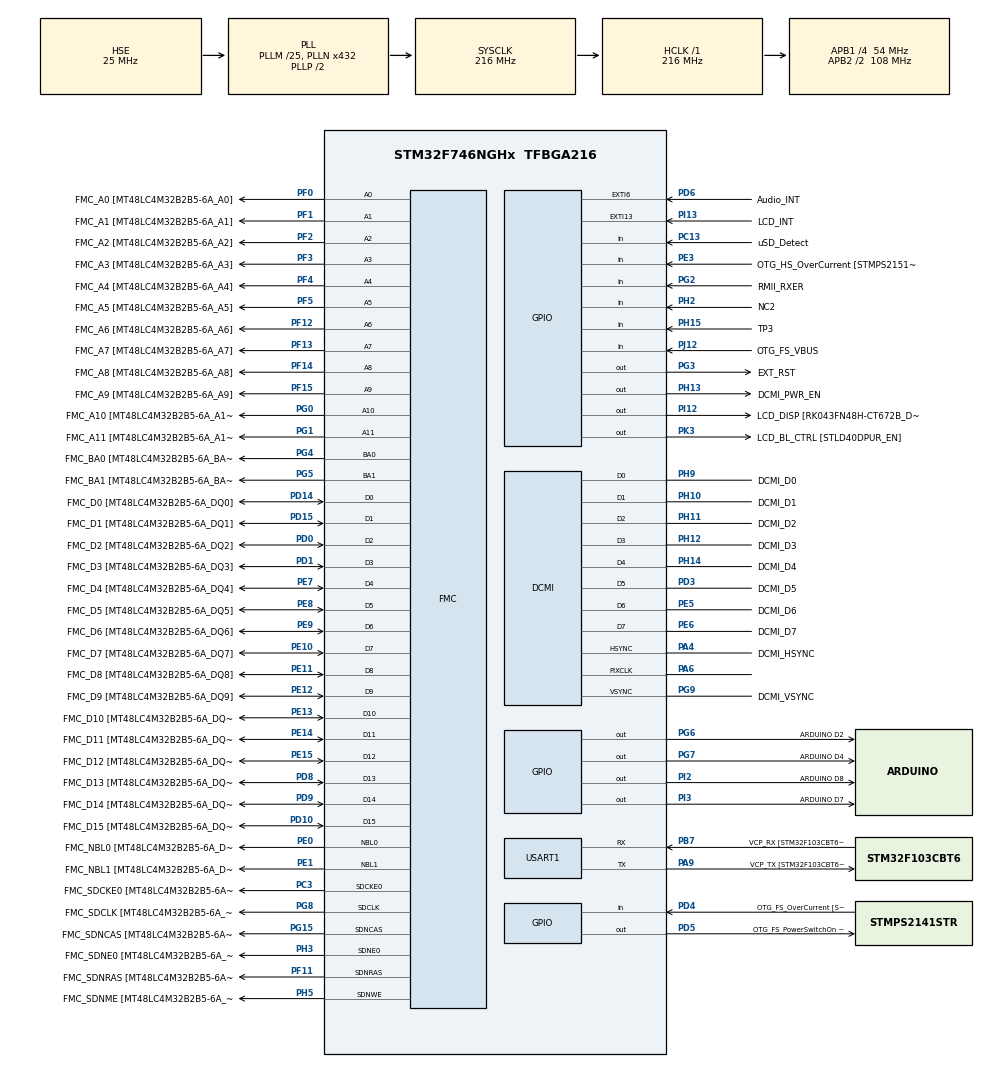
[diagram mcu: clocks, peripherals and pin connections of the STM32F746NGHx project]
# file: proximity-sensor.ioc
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CORTEX_M7.ART_ACCLERATOR_ENABLE=1
CORTEX_M7.CPU_DCache=Enabled
CORTEX_M7.CPU_ICache=Enabled
CORTEX_M7.PREFETCH_ENABLE=1
DCMI.PCKPolarity=DCMI_PCKPOLARITY_RISING
DCMI.VSPolarity=DCMI_VSPOLARITY_HIGH
Dma.DCMI.0.Direction=DMA_PERIPH_TO_MEMORY
Dma.DCMI.0.FIFOMode=DMA_FIFOMODE_ENABLE
Dma.DCMI.0.FIFOThreshold=DMA_FIFO_THRESHOLD_FULL
Dma.DCMI.0.Instance=DMA2_Stream1
Dma.DCMI.0.MemBurst=DMA_MBURST_INC4
Dma.DCMI.0.MemDataAlignment=DMA_MDATAALIGN_WORD
Dma.DCMI.0.MemInc=DMA_MINC_ENABLE
Dma.DCMI.0.Mode=DMA_CIRCULAR
Dma.DCMI.0.PeriphBurst=DMA_PBURST_SINGLE
Dma.DCMI.0.PeriphDataAlignment=DMA_PDATAALIGN_WORD
Dma.DCMI.0.PeriphInc=DMA_PINC_DISABLE
Dma.DCMI.0.Priority=DMA_PRIORITY_HIGH
Dma.Request0=DCMI
Mcu.Family=STM32F7
Mcu.Name=STM32F746NGHx
Mcu.Package=TFBGA216
NVIC.DCMI_IRQn=true\:0\:0\:false\:false\:true\:true
NVIC.DMA2_Stream1_IRQn=true\:0\:0\:false\:false\:true\:false
NVIC.PriorityGroup=NVIC_PRIORITYGROUP_4
NVIC.USART1_IRQn=true\:0\:0\:false\:false\:true\:true
PA0/WKUP.GPIO_Label=ARDUINO A0
PA0/WKUP.GPIO_Mode=GPIO_MODE_ANALOG
PA0/WKUP.GPIO_PuPd=GPIO_NOPULL
PA0/WKUP.Signal=ADCx_IN0
PA1.GPIO_Label=RMII_REF_CLK [LAN8742A-CZ-TR_REFCLK0]
PA1.Signal=ETH_REF_CLK
PA10.GPIO_Label=OTG_FS_ID
PA10.Signal=USB_OTG_FS_ID
PA11.GPIO_Label=OTG_FS_N
PA11.Signal=USB_OTG_FS_DM
PA12.GPIO_Label=OTG_FS_P
PA12.Signal=USB_OTG_FS_DP
PA13.GPIO_Label=SWDIO
PA13.Mode=Serial_Wire
PA13.Signal=SYS_JTMS-SWDIO
PA14.GPIO_Label=SWCLK
PA14.Mode=Serial_Wire
PA14.Signal=SYS_JTCK-SWCLK
PA15.GPIO_Label=ARDUINO PWM/D9
PA15.GPIO_ModeDefaultPP=GPIO_MODE_AF_PP
PA15.GPIO_PuPd=GPIO_NOPULL
PA15.GPIO_Speed=GPIO_SPEED_FREQ_LOW
PA15.Signal=S_TIM2_CH1_ETR
PA2.GPIO_Label=RMII_MDIO [LAN8742A-CZ-TR_MDIO]
PA2.Signal=ETH_MDIO
PA3.GPIO_Label=ULPI_D0 [USB3320C-EZK_D0]
PA3.Signal=USB_OTG_HS_ULPI_D0
PA4.GPIO_Label=DCMI_HSYNC
PA4.Mode=Slave_8_bits_External_Synchro
PA4.Signal=DCMI_HSYNC
PA5.GPIO_Label=ULPI_CLK [USB3320C-EZK_CLKOUT]
PA5.Signal=USB_OTG_HS_ULPI_CK
PA6.Mode=Slave_8_bits_External_Synchro
PA6.Signal=DCMI_PIXCLK
PA7.GPIO_Label=RMII_CRS_DV [LAN8742A-CZ-TR_CRS_DV]
PA7.Signal=ETH_CRS_DV
PA8.GPIO_Label=ARDUINO PWM/D5
PA8.GPIO_ModeDefaultPP=GPIO_MODE_AF_PP
PA8.GPIO_PuPd=GPIO_NOPULL
PA8.GPIO_Speed=GPIO_SPEED_FREQ_LOW
PA8.Signal=S_TIM1_CH1
PA9.GPIO_Label=VCP_TX [STM32F103CBT6_PA3]
PA9.GPIO_Mode=GPIO_MODE_AF_PP
PA9.GPIO_PuPd=GPIO_NOPULL
PA9.GPIO_Speed=GPIO_SPEED_FREQ_LOW
PA9.Mode=Asynchronous
PA9.Signal=USART1_TX
PB0.GPIO_Label=ULPI_D1 [USB3320C-EZK_D1]
PB0.Signal=USB_OTG_HS_ULPI_D1
PB1.GPIO_Label=ULPI_D2 [USB3320C-EZK_D2]
PB1.Signal=USB_OTG_HS_ULPI_D2
PB10.GPIO_Label=ULPI_D3 [USB3320C-EZK_D3]
PB10.Signal=USB_OTG_HS_ULPI_D3
PB11.GPIO_Label=ULPI_D4 [USB3320C-EZK_D4]
PB11.Signal=USB_OTG_HS_ULPI_D4
PB12.GPIO_Label=ULPI_D5 [USB3320C-EZK_D5]
PB12.Signal=USB_OTG_HS_ULPI_D5
PB13.GPIO_Label=ULPI_D6 [USB3320C-EZK_D6]
PB13.Signal=USB_OTG_HS_ULPI_D6
PB14.GPIO_Label=ARDUINO MISO/D12
PB14.GPIO_Mode=GPIO_MODE_AF_PP
PB14.GPIO_PuPd=GPIO_NOPULL
PB14.GPIO_Speed=GPIO_SPEED_FREQ_LOW
PB14.Signal=SPI2_MISO
PB15.GPIO_Label=ARDUINO MOSI/PWM/D11
PB15.GPIO_Mode=GPIO_MODE_AF_PP
PB15.GPIO_PuPd=GPIO_NOPULL
PB15.GPIO_Speed=GPIO_SPEED_FREQ_LOW
PB15.Signal=SPI2_MOSI
PB2.Signal=QUADSPI_CLK
PB3.GPIO_Label=SWO
PB3.Signal=SYS_JTDO-SWO
PB4.GPIO_Label=ARDUINO PWM/D3
PB4.GPIO_ModeDefaultPP=GPIO_MODE_AF_PP
PB4.GPIO_PuPd=GPIO_NOPULL
PB4.GPIO_Speed=GPIO_SPEED_FREQ_LOW
PB4.Signal=S_TIM3_CH1
PB5.GPIO_Label=ULPI_D7 [USB3320C-EZK_D7]
PB5.Signal=USB_OTG_HS_ULPI_D7
PB6.GPIO_Label=QSPI_NCS [N25Q128A13EF840E_S]
PB6.Signal=QUADSPI_BK1_NCS
PB7.GPIO_Label=VCP_RX [STM32F103CBT6_PA2]
PB7.GPIO_Mode=GPIO_MODE_AF_PP
PB7.GPIO_PuPd=GPIO_NOPULL
PB7.GPIO_Speed=GPIO_SPEED_FREQ_LOW
PB7.Mode=Asynchronous
PB7.Signal=USART1_RX
PB8.GPIO_Label=DCMI_SCL
PB8.GPIO_Mode=GPIO_MODE_AF_OD
PB8.GPIO_PuPd=GPIO_NOPULL
PB8.GPIO_Speed=GPIO_SPEED_FREQ_LOW
PB8.Signal=I2C1_SCL
PB9.GPIO_Label=DCMI_SDA
PB9.GPIO_Mode=GPIO_MODE_AF_OD
PB9.GPIO_PuPd=GPIO_NOPULL
PB9.GPIO_Speed=GPIO_SPEED_FREQ_LOW
PB9.Signal=I2C1_SDA
PC0.GPIO_Label=ULPI_STP [USB3320C-EZK_STP]
PC0.Signal=USB_OTG_HS_ULPI_STP
PC1.GPIO_Label=RMII_MDC [LAN8742A-CZ-TR_MDC]
PC1.Signal=ETH_MDC
PC10.GPIO_Label=SDMMC_D2
PC10.Signal=SDMMC1_D2
PC11.GPIO_Label=SDMMC_D3
PC11.Signal=SDMMC1_D3
PC12.GPIO_Label=SDMMC_CK
PC12.Signal=SDMMC1_CK
PC13.GPIO_Label=uSD_Detect
PC13.Signal=GPIO_Input
PC14/OSC32_IN.GPIO_Label=RCC_OSC32_IN
PC14/OSC32_IN.Mode=LSE-External-Oscillator
PC14/OSC32_IN.Signal=RCC_OSC32_IN
PC15/OSC32_OUT.GPIO_Label=RCC_OSC32_OUT
PC15/OSC32_OUT.Mode=LSE-External-Oscillator
PC15/OSC32_OUT.Signal=RCC_OSC32_OUT
PC2.GPIO_Label=ULPI_DIR [USB3320C-EZK_DIR]
PC2.Signal=USB_OTG_HS_ULPI_DIR
PC3.GPIO_Label=FMC_SDCKE0 [MT48LC4M32B2B5-6A_CKE]
PC3.Mode=SdramChipSelect1_1
PC3.Signal=FMC_SDCKE0
PC4.GPIO_Label=RMII_RXD0 [LAN8742A-CZ-TR_RXD0]
PC4.Signal=ETH_RXD0
PC5.GPIO_Label=RMII_RXD1 [LAN8742A-CZ-TR_RXD1]
PC5.Signal=ETH_RXD1
PC6.GPIO_Label=ARDUINO TX/D1
PC6.Signal=USART6_TX
PC7.GPIO_Label=ARDUINO RX/D0
PC7.Signal=USART6_RX
PC8.Signal=SDMMC1_D0
PC9.Signal=SDMMC1_D1
PD0.GPIO_Label=FMC_D2 [MT48LC4M32B2B5-6A_DQ2]
PD0.Signal=FMC_D2_DA2
PD1.GPIO_Label=FMC_D3 [MT48LC4M32B2B5-6A_DQ3]
PD1.Signal=FMC_D3_DA3
PD10.GPIO_Label=FMC_D15 [MT48LC4M32B2B5-6A_DQ15]
PD10.Signal=FMC_D15_DA15
PD11.GPIO_Label=QSPI_D0 [N25Q128A13EF840E_DQ0]
PD11.Signal=QUADSPI_BK1_IO0
PD12.GPIO_Label=QSPI_D1 [N25Q128A13EF840E_DQ1]
PD12.Signal=QUADSPI_BK1_IO1
PD13.GPIO_Label=QSPI_D3 [N25Q128A13EF840E_DQ3]
PD13.Signal=QUADSPI_BK1_IO3
PD14.GPIO_Label=FMC_D0 [MT48LC4M32B2B5-6A_DQ0]
PD14.Signal=FMC_D0_DA0
PD15.GPIO_Label=FMC_D1 [MT48LC4M32B2B5-6A_DQ1]
PD15.Signal=FMC_D1_DA1
PD2.GPIO_Label=SDMMC_CMD
PD2.Signal=SDMMC1_CMD
PD3.GPIO_Label=DCMI_D5
PD3.Mode=Slave_8_bits_External_Synchro
PD3.Signal=DCMI_D5
PD4.GPIO_Label=OTG_FS_OverCurrent [STMPS2141STR_Fault]
PD4.Signal=GPIO_Input
PD5.GPIO_Label=OTG_FS_PowerSwitchOn [STMPS2141STR_EN]
PD5.PinState=GPIO_PIN_SET
PD5.Signal=GPIO_Output
PD6.GPIO_Label=Audio_INT
PD6.GPIO_ModeDefaultEXTI=GPIO_MODE_EVT_RISING
PD6.Signal=GPXTI6
PD7.GPIO_Label=SPDIF_RX0 [74LVC1G04SE_4]
PD7.Signal=SPDIFRX_IN0
PD8.GPIO_Label=FMC_D13 [MT48LC4M32B2B5-6A_DQ13]
PD8.Signal=FMC_D13_DA13
PD9.GPIO_Label=FMC_D14 [MT48LC4M32B2B5-6A_DQ14]
PD9.Signal=FMC_D14_DA14
PE0.GPIO_Label=FMC_NBL0 [MT48LC4M32B2B5-6A_DQM0]
PE0.Signal=FMC_NBL0
PE1.GPIO_Label=FMC_NBL1 [MT48LC4M32B2B5-6A_DQM1]
PE1.Signal=FMC_NBL1
PE10.GPIO_Label=FMC_D7 [MT48LC4M32B2B5-6A_DQ7]
PE10.Signal=FMC_D7_DA7
PE11.GPIO_Label=FMC_D8 [MT48LC4M32B2B5-6A_DQ8]
PE11.Signal=FMC_D8_DA8
PE12.GPIO_Label=FMC_D9 [MT48LC4M32B2B5-6A_DQ9]
PE12.Signal=FMC_D9_DA9
PE13.GPIO_Label=FMC_D10 [MT48LC4M32B2B5-6A_DQ10]
PE13.Signal=FMC_D10_DA10
PE14.GPIO_Label=FMC_D11 [MT48LC4M32B2B5-6A_DQ11]
PE14.Signal=FMC_D11_DA11
PE15.GPIO_Label=FMC_D12 [MT48LC4M32B2B5-6A_DQ12]
PE15.Signal=FMC_D12_DA12
PE2.GPIO_Label=QSPI_D2 [N25Q128A13EF840E_DQ2]
PE2.Signal=QUADSPI_BK1_IO2
PE3.GPIO_Label=OTG_HS_OverCurrent [STMPS2151STR_FAULT]
PE3.Signal=GPIO_Input
PE4.GPIO_Label=LCD_B0 [RK043FN48H-CT672B_B0]
PE4.Signal=LTDC_B0
PE5.GPIO_Label=DCMI_D6
PE5.Mode=Slave_8_bits_External_Synchro
PE5.Signal=DCMI_D6
PE6.GPIO_Label=DCMI_D7
PE6.Mode=Slave_8_bits_External_Synchro
PE6.Signal=DCMI_D7
PE7.GPIO_Label=FMC_D4 [MT48LC4M32B2B5-6A_DQ4]
PE7.Signal=FMC_D4_DA4
PE8.GPIO_Label=FMC_D5 [MT48LC4M32B2B5-6A_DQ5]
PE8.Signal=FMC_D5_DA5
PE9.GPIO_Label=FMC_D6 [MT48LC4M32B2B5-6A_DQ6]
PE9.Signal=FMC_D6_DA6
PF0.GPIO_Label=FMC_A0 [MT48LC4M32B2B5-6A_A0]
PF0.Signal=FMC_A0
PF1.GPIO_Label=FMC_A1 [MT48LC4M32B2B5-6A_A1]
PF1.Signal=FMC_A1
PF10.GPIO_Label=ARDUINO A1
PF10.GPIO_Mode=GPIO_MODE_ANALOG
PF10.GPIO_PuPd=GPIO_NOPULL
PF10.Signal=ADC3_IN8
PF11.GPIO_Label=FMC_SDNRAS [MT48LC4M32B2B5-6A_RAS]
PF11.Signal=FMC_SDNRAS
PF12.GPIO_Label=FMC_A6 [MT48LC4M32B2B5-6A_A6]
PF12.Signal=FMC_A6
PF13.GPIO_Label=FMC_A7 [MT48LC4M32B2B5-6A_A7]
PF13.Signal=FMC_A7
PF14.GPIO_Label=FMC_A8 [MT48LC4M32B2B5-6A_A8]
PF14.Signal=FMC_A8
PF15.GPIO_Label=FMC_A9 [MT48LC4M32B2B5-6A_A9]
PF15.Signal=FMC_A9
PF2.GPIO_Label=FMC_A2 [MT48LC4M32B2B5-6A_A2]
PF2.Signal=FMC_A2
PF3.GPIO_Label=FMC_A3 [MT48LC4M32B2B5-6A_A3]
PF3.Signal=FMC_A3
PF4.GPIO_Label=FMC_A4 [MT48LC4M32B2B5-6A_A4]
PF4.Signal=FMC_A4
PF5.GPIO_Label=FMC_A5 [MT48LC4M32B2B5-6A_A5]
PF5.Signal=FMC_A5
PF6.GPIO_Label=ARDUINO A5
PF6.GPIO_Mode=GPIO_MODE_ANALOG
PF6.GPIO_PuPd=GPIO_NOPULL
PF6.Signal=ADC3_IN4
PF7.GPIO_Label=ARDUINO A4
PF7.GPIO_Mode=GPIO_MODE_ANALOG
PF7.GPIO_PuPd=GPIO_NOPULL
PF7.Signal=ADC3_IN5
PF8.GPIO_Label=ARDUINO A3
PF8.GPIO_Mode=GPIO_MODE_ANALOG
PF8.GPIO_PuPd=GPIO_NOPULL
PF8.Signal=ADC3_IN6
PF9.GPIO_Label=ARDUINO A2
PF9.GPIO_Mode=GPIO_MODE_ANALOG
PF9.GPIO_PuPd=GPIO_NOPULL
PF9.Signal=ADC3_IN7
PG0.GPIO_Label=FMC_A10 [MT48LC4M32B2B5-6A_A10]
PG0.Signal=FMC_A10
PG1.GPIO_Label=FMC_A11 [MT48LC4M32B2B5-6A_A11]
PG1.Signal=FMC_A11
PG10.GPIO_Label=SAI2_SDB [WM8994ECS/R_ADCDAT1]
PG10.Signal=SAI2_SD_B
PG11.GPIO_Label=RMII_TX_EN [LAN8742A-CZ-TR_TXEN]
PG11.Signal=ETH_TX_EN
PG12.GPIO_Label=LCD_B4 [RK043FN48H-CT672B_B4]
PG12.Signal=LTDC_B4
PG13.GPIO_Label=RMII_TXD0 [LAN8742A-CZ-TR_TXD0]
PG13.Signal=ETH_TXD0
PG14.GPIO_Label=RMII_TXD1 [LAN8742A-CZ-TR_TXD1]
PG14.Signal=ETH_TXD1
PG15.GPIO_Label=FMC_SDNCAS [MT48LC4M32B2B5-6A_CAS]
PG15.Signal=FMC_SDNCAS
PG2.GPIO_Label=RMII_RXER
PG2.Signal=GPIO_Input
PG3.GPIO_Label=EXT_RST
PG3.Signal=GPIO_Output
PG4.GPIO_Label=FMC_BA0 [MT48LC4M32B2B5-6A_BA0]
PG4.Signal=FMC_A14_BA0
PG5.GPIO_Label=FMC_BA1 [MT48LC4M32B2B5-6A_BA1]
PG5.Signal=FMC_A15_BA1
PG6.GPIO_Label=ARDUINO D2
PG6.Signal=GPIO_Output
PG7.GPIO_Label=ARDUINO D4
PG7.Signal=GPIO_Output
PG8.GPIO_Label=FMC_SDCLK [MT48LC4M32B2B5-6A_CLK]
PG8.Signal=FMC_SDCLK
PG9.GPIO_Label=DCMI_VSYNC
PG9.Mode=Slave_8_bits_External_Synchro
PG9.Signal=DCMI_VSYNC
PH0/OSC_IN.GPIO_Label=OSC_25M [NZ2520SB-25.00M_OUT]
PH0/OSC_IN.Mode=HSE-External-Oscillator
PH0/OSC_IN.Signal=RCC_OSC_IN
PH1/OSC_OUT.Mode=HSE-External-Oscillator
PH1/OSC_OUT.Signal=RCC_OSC_OUT
PH10.GPIO_Label=DCMI_D1
PH10.Mode=Slave_8_bits_External_Synchro
PH10.Signal=DCMI_D1
PH11.GPIO_Label=DCMI_D2
PH11.Mode=Slave_8_bits_External_Synchro
PH11.Signal=DCMI_D2
PH12.GPIO_Label=DCMI_D3
PH12.Mode=Slave_8_bits_External_Synchro
PH12.Signal=DCMI_D3
PH13.GPIO_Label=DCMI_PWR_EN
PH13.GPIO_Speed=GPIO_SPEED_FREQ_HIGH
PH13.Signal=GPIO_Output
PH14.GPIO_Label=DCMI_D4
PH14.Mode=Slave_8_bits_External_Synchro
PH14.Signal=DCMI_D4
PH15.GPIO_Label=TP3
PH15.Signal=GPIO_Input
PH2.GPIO_Label=NC2
PH2.Signal=GPIO_Input
PH3.GPIO_Label=FMC_SDNE0 [MT48LC4M32B2B5-6A_CS]
PH3.Mode=SdramChipSelect1_1
PH3.Signal=FMC_SDNE0
PH4.GPIO_Label=ULPI_NXT [USB3320C-EZK_NXT]
PH4.Signal=USB_OTG_HS_ULPI_NXT
PH5.GPIO_Label=FMC_SDNME [MT48LC4M32B2B5-6A_WE]
PH5.Signal=FMC_SDNWE
PH6.GPIO_Label=ARDUINO PWM/D6
PH6.Signal=S_TIM12_CH1
PH7.GPIO_Label=LCD_SCL [RK043FN48H-CT672B_SCL]
PH7.Signal=I2C3_SCL
PH8.GPIO_Label=LCD_SDA [RK043FN48H-CT672B_SDA]
PH8.Signal=I2C3_SDA
PH9.GPIO_Label=DCMI_D0
PH9.Mode=Slave_8_bits_External_Synchro
PH9.Signal=DCMI_D0
PI0.GPIO_Label=ARDUINO PWM/CS/D10
PI0.GPIO_ModeDefaultPP=GPIO_MODE_AF_PP
PI0.GPIO_PuPd=GPIO_NOPULL
PI0.GPIO_Speed=GPIO_SPEED_FREQ_LOW
PI0.Signal=S_TIM5_CH4
PI1.GPIO_Label=ARDUINO SCK/D13
PI1.GPIO_Mode=GPIO_MODE_AF_PP
PI1.GPIO_PuPd=GPIO_NOPULL
PI1.GPIO_Speed=GPIO_SPEED_FREQ_LOW
PI1.Signal=SPI2_SCK
PI10.GPIO_Label=LCD_HSYNC [RK043FN48H-CT672B_HSYNC]
PI10.Signal=LTDC_HSYNC
PI12.GPIO_Label=LCD_DISP [RK043FN48H-CT672B_DISP] 
PI12.Signal=GPIO_Output
PI13.GPIO_Label=LCD_INT
PI13.GPIO_ModeDefaultEXTI=GPIO_MODE_EVT_RISING
PI13.Signal=GPXTI13
PI14.GPIO_Label=LCD_CLK [RK043FN48H-CT672B_CLK]
PI14.Signal=LTDC_CLK
PI15.GPIO_Label=LCD_R0 [RK043FN48H-CT672B_R0]
PI15.Signal=LTDC_R0
PI2.GPIO_Label=ARDUINO D8
PI2.Signal=GPIO_Output
PI3.GPIO_Label=ARDUINO D7
PI3.Signal=GPIO_Output
PI4.GPIO_Label=SAI2_MCLKA [WM8994ECS/R_MCLK1]
PI4.Signal=SAI2_MCLK_A
PI5.GPIO_Label=SAI2_SCKA [WM8994ECS/R_BCLK1]
PI5.Signal=SAI2_SCK_A
PI6.GPIO_Label=SAI2_SDA [WM8994ECS/R_DACDAT1]
PI6.Signal=SAI2_SD_A
PI7.GPIO_Label=SAI2_FSA [WM8994ECS/R_LRCLK1]
PI7.Signal=SAI2_FS_A
PI8.GPIO_Label=NC1 [TP2]
PI8.Signal=RTC_TS
PI9.GPIO_Label=LCD_VSYNC [RK043FN48H-CT672B_VSYNC]
PI9.Signal=LTDC_VSYNC
PJ0.GPIO_Label=LCD_R1 [RK043FN48H-CT672B_R1]
PJ0.Signal=LTDC_R1
PJ1.GPIO_Label=LCD_R2 [RK043FN48H-CT672B_R2]
PJ1.Signal=LTDC_R2
PJ10.GPIO_Label=LCD_G3 [RK043FN48H-CT672B_G3]
PJ10.Signal=LTDC_G3
PJ11.GPIO_Label=LCD_G4 [RK043FN48H-CT672B_G4]
PJ11.Signal=LTDC_G4
PJ12.GPIO_Label=OTG_FS_VBUS
PJ12.Signal=GPIO_Input
PJ13.GPIO_Label=LCD_B1 [RK043FN48H-CT672B_B1]
PJ13.Signal=LTDC_B1
PJ14.GPIO_Label=LCD_B2 [RK043FN48H-CT672B_B2]
PJ14.Signal=LTDC_B2
PJ15.GPIO_Label=LCD_B3 [RK043FN48H-CT672B_B3]
PJ15.Signal=LTDC_B3
PJ2.GPIO_Label=LCD_R3 [RK043FN48H-CT672B_R3]
PJ2.Signal=LTDC_R3
PJ3.GPIO_Label=LCD_R4 [RK043FN48H-CT672B_R4]
PJ3.Signal=LTDC_R4
PJ4.GPIO_Label=LCD_R5 [RK043FN48H-CT672B_R5]
PJ4.Signal=LTDC_R5
PJ5.GPIO_Label=LCD_R6 [RK043FN48H-CT672B_R6]
PJ5.Signal=LTDC_R6
PJ6.GPIO_Label=LCD_R7 [RK043FN48H-CT672B_R7]
PJ6.Signal=LTDC_R7
PJ7.GPIO_Label=LCD_G0 [RK043FN48H-CT672B_G0]
PJ7.Signal=LTDC_G0
PJ8.GPIO_Label=LCD_G1 [RK043FN48H-CT672B_G1]
PJ8.Signal=LTDC_G1
PJ9.GPIO_Label=LCD_G2 [RK043FN48H-CT672B_G2]
PJ9.Signal=LTDC_G2
PK0.GPIO_Label=LCD_G5 [RK043FN48H-CT672B_G5]
PK0.Signal=LTDC_G5
PK1.GPIO_Label=LCD_G6 [RK043FN48H-CT672B_G6]
PK1.Signal=LTDC_G6
PK2.GPIO_Label=LCD_G7 [RK043FN48H-CT672B_G7]
PK2.Signal=LTDC_G7
PK3.GPIO_Label=LCD_BL_CTRL [STLD40DPUR_EN]
PK3.Signal=GPIO_Output
PK4.GPIO_Label=LCD_B5 [RK043FN48H-CT672B_B5]
PK4.Signal=LTDC_B5
PK5.GPIO_Label=LCD_B6 [RK043FN48H-CT672B_B6]
PK5.Signal=LTDC_B6
PK6.GPIO_Label=LCD_B7 [RK043FN48H-CT672B_B7]
PK6.Signal=LTDC_B7
PK7.GPIO_Label=LCD_DE [RK043FN48H-CT672B_DE]
PK7.Signal=LTDC_DE
ProjectManager.HeapSize=0x200
ProjectManager.StackSize=0x400
ProjectManager.TargetToolchain=TrueSTUDIO
RCC.AHBFreq_Value=216000000
RCC.APB1CLKDivider=RCC_HCLK_DIV4
RCC.APB1Freq_Value=54000000
RCC.APB1TimFreq_Value=108000000
RCC.APB2CLKDivider=RCC_HCLK_DIV2
RCC.APB2Freq_Value=108000000
RCC.APB2TimFreq_Value=216000000
RCC.CortexFreq_Value=216000000
RCC.HCLKFreq_Value=216000000
RCC.HSE_VALUE=25000000
RCC.HSI_VALUE=16000000
RCC.PLLI2SN=100
RCC.PLLM=25
RCC.PLLN=432
RCC.PLLQ=9
RCC.PLLSAIN=100
RCC.PLLSourceVirtual=RCC_PLLSOURCE_HSE
RCC.SDMMCClockSelection=RCC_SDMMC1CLKSOURCE_CLK48
RCC.SYSCLKFreq_VALUE=216000000
RCC.SYSCLKSource=RCC_SYSCLKSOURCE_PLLCLK
RCC.USBFreq_Value=48000000
RCC.VCOOutputFreq_Value=432000000
SH.ADCx_IN0.0=ADC3_IN0
SH.FMC_A0.0=FMC_A0,12b-sda1
SH.FMC_A1.0=FMC_A1,12b-sda1
SH.FMC_A10.0=FMC_A10,12b-sda1
SH.FMC_A11.0=FMC_A11,12b-sda1
SH.FMC_A14_BA0.0=FMC_BA0,FourSdramBanks1
SH.FMC_A15_BA1.0=FMC_BA1,FourSdramBanks1
SH.FMC_A2.0=FMC_A2,12b-sda1
SH.FMC_A3.0=FMC_A3,12b-sda1
SH.FMC_A4.0=FMC_A4,12b-sda1
SH.FMC_A5.0=FMC_A5,12b-sda1
SH.FMC_A6.0=FMC_A6,12b-sda1
SH.FMC_A7.0=FMC_A7,12b-sda1
SH.FMC_A8.0=FMC_A8,12b-sda1
SH.FMC_A9.0=FMC_A9,12b-sda1
SH.FMC_D0_DA0.0=FMC_D0,sd-16b-d1
SH.FMC_D10_DA10.0=FMC_D10,sd-16b-d1
SH.FMC_D11_DA11.0=FMC_D11,sd-16b-d1
SH.FMC_D12_DA12.0=FMC_D12,sd-16b-d1
SH.FMC_D13_DA13.0=FMC_D13,sd-16b-d1
SH.FMC_D14_DA14.0=FMC_D14,sd-16b-d1
SH.FMC_D15_DA15.0=FMC_D15,sd-16b-d1
SH.FMC_D1_DA1.0=FMC_D1,sd-16b-d1
SH.FMC_D2_DA2.0=FMC_D2,sd-16b-d1
SH.FMC_D3_DA3.0=FMC_D3,sd-16b-d1
SH.FMC_D4_DA4.0=FMC_D4,sd-16b-d1
SH.FMC_D5_DA5.0=FMC_D5,sd-16b-d1
SH.FMC_D6_DA6.0=FMC_D6,sd-16b-d1
SH.FMC_D7_DA7.0=FMC_D7,sd-16b-d1
SH.FMC_D8_DA8.0=FMC_D8,sd-16b-d1
SH.FMC_D9_DA9.0=FMC_D9,sd-16b-d1
SH.FMC_NBL0.0=FMC_NBL0,Sd2ByteEnable1
SH.FMC_NBL1.0=FMC_NBL1,Sd2ByteEnable1
SH.FMC_SDCLK.0=FMC_SDCLK,12b-sda1
SH.FMC_SDNCAS.0=FMC_SDNCAS,12b-sda1
SH.FMC_SDNRAS.0=FMC_SDNRAS,12b-sda1
SH.FMC_SDNWE.0=FMC_SDNWE,12b-sda1
SH.S_TIM12_CH1.0=TIM12_CH1
SH.S_TIM1_CH1.0=TIM1_CH1
SH.S_TIM2_CH1_ETR.0=TIM2_CH1
SH.S_TIM3_CH1.0=TIM3_CH1
SH.S_TIM5_CH4.0=TIM5_CH4
USART1.VirtualMode-Asynchronous=VM_ASYNC
USART1.WordLength=WORDLENGTH_8B
board=32F746GDISCOVERY

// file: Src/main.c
/**
  ******************************************************************************
  * @file           : main.c
  * @brief          : Main program body
  ******************************************************************************
  ** This notice applies to any and all portions of this file
  * that are not between comment pairs USER CODE BEGIN and
  * USER CODE END. Other portions of this file, whether
  * inserted by the user or by software development tools
  * are owned by their respective copyright owners.
  *
  * COPYRIGHT(c) 2018 STMicroelectronics
  *
  * Redistribution and use in source and binary forms, with or without modification,
  * are permitted provided that the following conditions are met:
  *   1. Redistributions of source code must retain the above copyright notice,
  *      this list of conditions and the following disclaimer.
  *   2. Redistributions in binary form must reproduce the above copyright notice,
  *      this list of conditions and the following disclaimer in the documentation
  *      and/or other materials provided with the distribution.
  *   3. Neither the name of STMicroelectronics nor the names of its contributors
  *      may be used to endorse or promote products derived from this software
  *      without specific prior written permission.
  *
  * THIS SOFTWARE IS PROVIDED BY THE COPYRIGHT HOLDERS AND CONTRIBUTORS "AS IS"
  * AND ANY EXPRESS OR IMPLIED WARRANTIES, INCLUDING, BUT NOT LIMITED TO, THE
  * IMPLIED WARRANTIES OF MERCHANTABILITY AND FITNESS FOR A PARTICULAR PURPOSE ARE
  * DISCLAIMED. IN NO EVENT SHALL THE COPYRIGHT HOLDER OR CONTRIBUTORS BE LIABLE
  * FOR ANY DIRECT, INDIRECT, INCIDENTAL, SPECIAL, EXEMPLARY, OR CONSEQUENTIAL
  * DAMAGES (INCLUDING, BUT NOT LIMITED TO, PROCUREMENT OF SUBSTITUTE GOODS OR
  * SERVICES; LOSS OF USE, DATA, OR PROFITS; OR BUSINESS INTERRUPTION) HOWEVER
  * CAUSED AND ON ANY THEORY OF LIABILITY, WHETHER IN CONTRACT, STRICT LIABILITY,
  * OR TORT (INCLUDING NEGLIGENCE OR OTHERWISE) ARISING IN ANY WAY OUT OF THE USE
  * OF THIS SOFTWARE, EVEN IF ADVISED OF THE POSSIBILITY OF SUCH DAMAGE.
  *
  ******************************************************************************
  */
#include "main.h"
#include "stm32f7xx_hal.h"
#include "dcmi.h"
#include "dma.h"
#include "usart.h"
#include "gpio.h"
#include "fmc.h"

/* USER CODE BEGIN Includes */
#include "usb_device.h"
#include "usbd_cdc_if.h"
#include "config.h"
#include "stm32746g_discovery.h"
#include "stm32746g_discovery_sdram.h"
#include "ov9655.h"
#include "rk043fn48h.h"
#include "fonts.h"
#include "camera.h"

#include "prox_sensor.h"
#include "prox_sensor_console.h"
/* USER CODE END Includes */

/* USER CODE BEGIN PV */
/* Private variables ---------------------------------------------------------*/

typedef struct
{
	uint32_t TextColor;
	uint32_t BackColor;
	sFONT
	*pFont;
}LCD_DrawPropTypeDef;

typedef struct
{
	int16_t X;
	int16_t Y;
}Point, *pPoint;

static LCD_DrawPropTypeDef DrawProp[2];

LTDC_HandleTypeDef hltdc;
LTDC_LayerCfgTypeDef layer_cfg;
static RCC_PeriphCLKInitTypeDef periph_clk_init_struct;

/* Image size */
uint32_t Im_size = 0;

/* USER CODE END PV */

void SystemClock_Config(void);

/* USER CODE BEGIN PFP */
/* Private function prototypes -----------------------------------------------*/

static void LTDC_Init(uint32_t , uint16_t , uint16_t , uint16_t, uint16_t);
void LCD_GPIO_Init(LTDC_HandleTypeDef *, void *);

/* USER CODE END PFP */

/* USER CODE BEGIN 0 */
static void MPU_Config (void)
{
  MPU_Region_InitTypeDef MPU_InitStruct;

  /* Disable the MPU */
  HAL_MPU_Disable();

  /* Configure the MPU attributes for SDRAM */
  MPU_InitStruct.Enable = MPU_REGION_ENABLE;
  MPU_InitStruct.BaseAddress = 0xC0000000;
  MPU_InitStruct.Size = MPU_REGION_SIZE_4MB;
  MPU_InitStruct.AccessPermission = MPU_REGION_FULL_ACCESS;
  MPU_InitStruct.IsBufferable = MPU_ACCESS_NOT_BUFFERABLE;
  MPU_InitStruct.IsCacheable = MPU_ACCESS_NOT_CACHEABLE;
  MPU_InitStruct.IsShareable = MPU_ACCESS_NOT_SHAREABLE;
  MPU_InitStruct.Number = MPU_REGION_NUMBER0;
  MPU_InitStruct.TypeExtField = MPU_TEX_LEVEL1;
  MPU_InitStruct.SubRegionDisable = 0x00;
  MPU_InitStruct.DisableExec = MPU_INSTRUCTION_ACCESS_DISABLE;

  HAL_MPU_ConfigRegion(&MPU_InitStruct);

  /* Enable the MPU */
  HAL_MPU_Enable(MPU_PRIVILEGED_DEFAULT);
}

void perform();

/* USER CODE END 0 */

int main(void)
{

  /* Enable I-Cache-------------------------------------------------------------*/
  SCB_EnableICache();

  /* Enable D-Cache-------------------------------------------------------------*/
  SCB_EnableDCache();

  /* MCU Configuration----------------------------------------------------------*/

  /* Reset of all peripherals, Initializes the Flash interface and the Systick. */
  HAL_Init();

  /* Configure the system clock */
  SystemClock_Config();

  /* Initialize all configured peripherals */
  MX_GPIO_Init();
  MX_DMA_Init();
  MX_DCMI_Init();
  MX_FMC_Init();
  MX_USART1_UART_Init();
  /* USER CODE BEGIN 2 */
  MX_USB_DEVICE_Init();
  ProxSensor_Init(FRAME_BUFFER);
  ProxSensor_Console_Init();

  LTDC_Init(FRAME_BUFFER, 0, 0, CAM_IMG_WIDTH, CAM_IMG_HEIGHT);
  BSP_SDRAM_Init();

#ifdef CAM_R_QQVGA
  CAMERA_Init(CAMERA_R160x120);
#elif defined CAM_R_QVGA
  CAMERA_Init(CAMERA_R320x240);
#elif defined CAM_R_VGA
  CAMERA_Init(CAMERA_R640x480);
#endif

  //Delay for the camera to output correct data
  HAL_Delay(1000);
  Im_size = CAM_IMG_SIZE * 2 / 4;
  MPU_Config();

  /* USER CODE END 2 */

  /* Infinite loop */
  /* USER CODE BEGIN WHILE */

  while (1)
  {
	  ProxSensor_Console_Perform();
	  perform();
  /* USER CODE END WHILE */

  }

}

void SystemClock_Config(void)
{

  RCC_OscInitTypeDef RCC_OscInitStruct;
  RCC_ClkInitTypeDef RCC_ClkInitStruct;
  RCC_PeriphCLKInitTypeDef PeriphClkInitStruct;

    /**Configure the main internal regulator output voltage
    */
  __HAL_RCC_PWR_CLK_ENABLE();

  __HAL_PWR_VOLTAGESCALING_CONFIG(PWR_REGULATOR_VOLTAGE_SCALE1);

    /**Initializes the CPU, AHB and APB busses clocks
    */
  RCC_OscInitStruct.OscillatorType = RCC_OSCILLATORTYPE_HSE;
  RCC_OscInitStruct.HSEState = RCC_HSE_ON;
  RCC_OscInitStruct.PLL.PLLState = RCC_PLL_ON;
  RCC_OscInitStruct.PLL.PLLSource = RCC_PLLSOURCE_HSE;
  RCC_OscInitStruct.PLL.PLLM = 25;
  RCC_OscInitStruct.PLL.PLLN = 432;
  RCC_OscInitStruct.PLL.PLLP = RCC_PLLP_DIV2;
  RCC_OscInitStruct.PLL.PLLQ = 9;
  if (HAL_RCC_OscConfig(&RCC_OscInitStruct) != HAL_OK)
  {
    _Error_Handler(__FILE__, __LINE__);
  }

    /**Activate the Over-Drive mode
    */
  if (HAL_PWREx_EnableOverDrive() != HAL_OK)
  {
    _Error_Handler(__FILE__, __LINE__);
  }

    /**Initializes the CPU, AHB and APB busses clocks
    */
  RCC_ClkInitStruct.ClockType = RCC_CLOCKTYPE_HCLK|RCC_CLOCKTYPE_SYSCLK
                              |RCC_CLOCKTYPE_PCLK1|RCC_CLOCKTYPE_PCLK2;
  RCC_ClkInitStruct.SYSCLKSource = RCC_SYSCLKSOURCE_PLLCLK;
  RCC_ClkInitStruct.AHBCLKDivider = RCC_SYSCLK_DIV1;
  RCC_ClkInitStruct.APB1CLKDivider = RCC_HCLK_DIV4;
  RCC_ClkInitStruct.APB2CLKDivider = RCC_HCLK_DIV2;

  if (HAL_RCC_ClockConfig(&RCC_ClkInitStruct, FLASH_LATENCY_7) != HAL_OK)
  {
    _Error_Handler(__FILE__, __LINE__);
  }

  PeriphClkInitStruct.PeriphClockSelection = RCC_PERIPHCLK_USART1;
  PeriphClkInitStruct.Usart1ClockSelection = RCC_USART1CLKSOURCE_PCLK2;
  if (HAL_RCCEx_PeriphCLKConfig(&PeriphClkInitStruct) != HAL_OK)
  {
    _Error_Handler(__FILE__, __LINE__);
  }

    /**Configure the Systick interrupt time
    */
  HAL_SYSTICK_Config(HAL_RCC_GetHCLKFreq()/1000);

    /**Configure the Systick
    */
  HAL_SYSTICK_CLKSourceConfig(SYSTICK_CLKSOURCE_HCLK);

  /* SysTick_IRQn interrupt configuration */
  HAL_NVIC_SetPriority(SysTick_IRQn, 0, 0);
}

/* USER CODE BEGIN 4 */
void LCD_GPIO_Init(LTDC_HandleTypeDef *hltdc, void *Params)
{
	GPIO_InitTypeDef gpio_init_structure;
	/* Enable the LTDC and DMA2D clocks */
	__HAL_RCC_LTDC_CLK_ENABLE();
	__HAL_RCC_DMA2D_CLK_ENABLE();
	/* Enable GPIOs clock */
	__HAL_RCC_GPIOE_CLK_ENABLE();
	__HAL_RCC_GPIOG_CLK_ENABLE();
	__HAL_RCC_GPIOI_CLK_ENABLE();
	__HAL_RCC_GPIOJ_CLK_ENABLE();
	__HAL_RCC_GPIOK_CLK_ENABLE();
	/*** LTDC Pins configuration ***/
	/* GPIOE configuration */
	gpio_init_structure.Pin = GPIO_PIN_4;
	gpio_init_structure.Mode = GPIO_MODE_AF_PP;
	gpio_init_structure.Pull = GPIO_NOPULL;
	gpio_init_structure.Speed = GPIO_SPEED_FAST;
	gpio_init_structure.Alternate = GPIO_AF14_LTDC;
	HAL_GPIO_Init(GPIOE, &gpio_init_structure);
	/* GPIOG configuration */
	gpio_init_structure.Pin = GPIO_PIN_12;
	gpio_init_structure.Mode = GPIO_MODE_AF_PP;
	gpio_init_structure.Alternate = GPIO_AF9_LTDC;
	HAL_GPIO_Init(GPIOG, &gpio_init_structure);
	/* GPIOI LTDC alternate configuration */
	gpio_init_structure.Pin	= GPIO_PIN_9 | GPIO_PIN_10 | GPIO_PIN_13 |
						      GPIO_PIN_14 | GPIO_PIN_15;
	gpio_init_structure.Mode = GPIO_MODE_AF_PP;
	gpio_init_structure.Alternate = GPIO_AF14_LTDC;
	HAL_GPIO_Init(GPIOI, &gpio_init_structure);
	/* GPIOJ configuration */
	gpio_init_structure.Pin = GPIO_PIN_0 | GPIO_PIN_1 | GPIO_PIN_2 |
	GPIO_PIN_3 | GPIO_PIN_4 | GPIO_PIN_5 | GPIO_PIN_6 | GPIO_PIN_7 | GPIO_PIN_5
	| GPIO_PIN_6 | GPIO_PIN_7 |GPIO_PIN_8 | GPIO_PIN_9 | GPIO_PIN_10 |
	GPIO_PIN_11 | GPIO_PIN_13 | GPIO_PIN_14 | GPIO_PIN_15;
	gpio_init_structure.Mode = GPIO_MODE_AF_PP;
	gpio_init_structure.Alternate = GPIO_AF14_LTDC;
	HAL_GPIO_Init(GPIOJ, &gpio_init_structure);
	/* GPIOK configuration */
	gpio_init_structure.Pin 	= GPIO_PIN_0 | GPIO_PIN_1 | GPIO_PIN_2 |
	GPIO_PIN_4 | GPIO_PIN_5 | GPIO_PIN_6 | GPIO_PIN_7;
	gpio_init_structure.Mode = GPIO_MODE_AF_PP;
	gpio_init_structure.Alternate = GPIO_AF14_LTDC;
	HAL_GPIO_Init(GPIOK, &gpio_init_structure);
	/* LCD_DISP GPIO configuration */
	gpio_init_structure.Pin = GPIO_PIN_12;
	/* LCD_DISP pin has to be manually controlled */
	gpio_init_structure.Mode = GPIO_MODE_OUTPUT_PP;
	HAL_GPIO_Init(GPIOI, &gpio_init_structure);
	/* LCD_BL_CTRL GPIO configuration */
	gpio_init_structure.Pin 	= GPIO_PIN_3;
	/* LCD_BL_CTRL pin has to be manually controlled */
	gpio_init_structure.Mode = GPIO_MODE_OUTPUT_PP;
	HAL_GPIO_Init(GPIOK, &gpio_init_structure);
}

static void LTDC_Init(uint32_t FB_Address, uint16_t Xpos, uint16_t Ypos, uint16_t Width, uint16_t Height)
{
	/* Timing Configuration */
	hltdc.Init.HorizontalSync = (RK043FN48H_HSYNC - 1);
	hltdc.Init.VerticalSync = (RK043FN48H_VSYNC - 1);
	hltdc.Init.AccumulatedHBP = (RK043FN48H_HSYNC + RK043FN48H_HBP - 1);
	hltdc.Init.AccumulatedVBP = (RK043FN48H_VSYNC + RK043FN48H_VBP - 1);
	hltdc.Init.AccumulatedActiveH = (RK043FN48H_HEIGHT + RK043FN48H_VSYNC +	RK043FN48H_VBP - 1);
	hltdc.Init.AccumulatedActiveW = (RK043FN48H_WIDTH + RK043FN48H_HSYNC + 	RK043FN48H_HBP - 1);
	hltdc.Init.TotalHeigh = (RK043FN48H_HEIGHT + RK043FN48H_VSYNC +	RK043FN48H_VBP + RK043FN48H_VFP - 1);
	hltdc.Init.TotalWidth = (RK043FN48H_WIDTH + RK043FN48H_HSYNC +	RK043FN48H_HBP + RK043FN48H_HFP - 1);
	/* LCD clock configuration */
	periph_clk_init_struct.PeriphClockSelection = RCC_PERIPHCLK_LTDC;
	periph_clk_init_struct.PLLSAI.PLLSAIN = 192;
	periph_clk_init_struct.PLLSAI.PLLSAIR = RK043FN48H_FREQUENCY_DIVIDER;
	periph_clk_init_struct.PLLSAIDivR = RCC_PLLSAIDIVR_4;
	HAL_RCCEx_PeriphCLKConfig(&periph_clk_init_struct);
	/* Initialize the LCD pixel width and pixel height */
	hltdc.LayerCfg->ImageWidth	= RK043FN48H_WIDTH;
	hltdc.LayerCfg->ImageHeight = RK043FN48H_HEIGHT;
	hltdc.Init.Backcolor.Blue = 0;/* Background value */
	hltdc.Init.Backcolor.Green = 0;
	hltdc.Init.Backcolor.Red = 0;
	/* Polarity */
	hltdc.Init.HSPolarity = LTDC_HSPOLARITY_AL;
	hltdc.Init.VSPolarity = LTDC_VSPOLARITY_AL;
	hltdc.Init.DEPolarity = LTDC_DEPOLARITY_AL;
	hltdc.Init.PCPolarity = LTDC_PCPOLARITY_IPC;
	hltdc.Instance = LTDC;
	if(HAL_LTDC_GetState(&hltdc) == HAL_LTDC_STATE_RESET)
	{
		LCD_GPIO_Init(&hltdc, NULL);
	}
	HAL_LTDC_Init(&hltdc);
	/* Assert display enable LCD_DISP pin */
	HAL_GPIO_WritePin(GPIOI, GPIO_PIN_12, GPIO_PIN_SET);
	/* Assert backlight LCD_BL_CTRL pin */
	HAL_GPIO_WritePin(GPIOK, GPIO_PIN_3, GPIO_PIN_SET);
	DrawProp[0].pFont = &Font24;

	/* Layer Init */
	layer_cfg.WindowX0 = Xpos;
	layer_cfg.WindowX1 = Width + Xpos;
	layer_cfg.WindowY0 = Ypos;
	layer_cfg.WindowY1 = Height + Ypos;
	layer_cfg.PixelFormat = LTDC_PIXEL_FORMAT_RGB565;
	layer_cfg.FBStartAdress = FB_Address;
	layer_cfg.Alpha = 255;
	layer_cfg.Alpha0 = 0;
	layer_cfg.Backcolor.Blue = 0;
	layer_cfg.Backcolor.Green = 0;
	layer_cfg.Backcolor.Red = 0;
	layer_cfg.BlendingFactor1 = LTDC_BLENDING_FACTOR1_PAxCA;
	layer_cfg.BlendingFactor2 = LTDC_BLENDING_FACTOR2_PAxCA;
	layer_cfg.ImageWidth = Width;
	layer_cfg.ImageHeight = Height;
	HAL_LTDC_ConfigLayer(&hltdc, &layer_cfg, 0);

	/* Layer 2 Init */
	layer_cfg.FBStartAdress = FRAME_BUFFER_2;
	HAL_LTDC_ConfigLayer(&hltdc, &layer_cfg, 1);

	DrawProp[1].BackColor = ((uint32_t)0xFFFFFFFF);
	DrawProp[1].pFont = &Font24;
	DrawProp[1].TextColor = ((uint32_t)0xFF000000);
}

void showLayer(uint8_t layer_no)
{
	/* Set proper alpha values */
	if(0 == layer_no)
	{
		LTDC_Layer1->CACR = 255;
		LTDC_Layer2->CACR = 0;
	}
	else
	{
		LTDC_Layer1->CACR = 0;
		LTDC_Layer2->CACR = 255;
	}

	/* Reload screen */
	LTDC->SRCR=2;
}

void perform()
{
	static uint8_t layer = 0;
	uint32_t addr = FRAME_BUFFER;

	showLayer(0);

	if(0 == layer)
	{
		showLayer(1);
		layer = 1;
	}
	else
	{
		showLayer(0);
		layer = 0;
		addr = FRAME_BUFFER_2;
	}

//	SET_DEBUG_PIN4;
	HAL_DCMI_Start_DMA(&hdcmi, DCMI_MODE_SNAPSHOT, addr, Im_size);
	HAL_DCMI_Stop(&hdcmi);
//	RESET_DEBUG_PIN4;

	SET_DEBUG_PIN2;
	ProxSensor_Perform(addr);
	RESET_DEBUG_PIN2;

}

/* USER CODE END 4 */

void _Error_Handler(char *file, int line)
{
  while(1)
  {
  }
}

/************************ (C) COPYRIGHT STMicroelectronics *****END OF FILE****/
